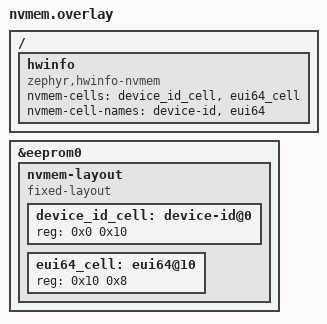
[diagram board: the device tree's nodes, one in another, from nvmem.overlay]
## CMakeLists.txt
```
# SPDX-License-Identifier: Apache-2.0

cmake_minimum_required(VERSION 3.28.0)
find_package(Zephyr REQUIRED HINTS $ENV{ZEPHYR_BASE})
project(integration)

target_sources(app PRIVATE src/main.c)
target_sources_ifdef(CONFIG_HWINFO_NVMEM app PRIVATE src/nvmem.c)
```

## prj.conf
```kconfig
CONFIG_HWINFO=y
CONFIG_ZTEST=y
```

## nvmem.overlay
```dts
/*
 * SPDX-FileCopyrightText: Copyright (c) 2026 Basalte bv
 * SPDX-License-Identifier: Apache-2.0
 */

/ {
	hwinfo {
		compatible = "zephyr,hwinfo-nvmem";
		nvmem-cells = <&device_id_cell>, <&eui64_cell>;
		nvmem-cell-names = "device-id", "eui64";
	};
};

&eeprom0 {
	nvmem-layout {
		compatible = "fixed-layout";
		#address-cells = <1>;
		#size-cells = <1>;

		device_id_cell: device-id@0 {
			reg = <0x0 0x10>;
			#nvmem-cell-cells = <0>;
		};

		eui64_cell: eui64@10 {
			reg = <0x10 0x8>;
			#nvmem-cell-cells = <0>;
		};
	};
};
```

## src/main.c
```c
/*
 * Copyright (c) 2019 Alexander Wachter
 *
 * SPDX-License-Identifier: Apache-2.0
 */
#include <zephyr/drivers/hwinfo.h>
#include <zephyr/ztest.h>
#include <strings.h>
#include <errno.h>

/*
 * @addtogroup t_hwinfo_get_device_id_api
 * @{
 * @defgroup t_hwinfo_get_device_id test_hwinfo_get_device_id
 * @brief TestPurpose: verify device id get works
 * @details
 * - Test Steps
 *   -# Read the ID
 *   -# Check if to many bytes are written to the buffer
 *   -# Check if UID is plausible
 * - Expected Results
 *   -# Device uid with correct length should be written to the buffer.
 * @}
 */

#define BUFFER_LENGTH 17
#define BUFFER_CANARY 0xFF

ZTEST(hwinfo_device_id_api, test_device_id_get)
{
	uint8_t buffer_1[BUFFER_LENGTH];
	uint8_t buffer_2[BUFFER_LENGTH];
	ssize_t length_read_1, length_read_2;
	int i;

	length_read_1 = hwinfo_get_device_id(buffer_1, 1);
	if (length_read_1 == -ENOSYS) {
		ztest_test_skip();
		return;
	}

	zassert_false((length_read_1 < 0),
		      "Unexpected negative return value: %zd", length_read_1);
	zassert_not_equal(length_read_1, 0, "Zero bytes read");
	zassert_equal(length_read_1, 1, "Length not adhered");

	memset(buffer_1, BUFFER_CANARY, sizeof(buffer_1));

	length_read_1 = hwinfo_get_device_id(buffer_1, BUFFER_LENGTH - 1);
	zassert_equal(buffer_1[length_read_1], BUFFER_CANARY,
		      "Too many bytes are written");

	memcpy(buffer_2, buffer_1, length_read_1);

	for (i = 0; i < BUFFER_LENGTH; i++) {
		buffer_1[i] ^= 0xA5;
	}

	length_read_2 = hwinfo_get_device_id(buffer_1, BUFFER_LENGTH - 1);
	zassert_equal(length_read_1, length_read_2, "Length varied");

	zassert_equal(buffer_1[length_read_1], (BUFFER_CANARY ^ 0xA5),
		      "Too many bytes are written");

	for (i = 0; i < length_read_1; i++) {
		zassert_equal(buffer_1[i], buffer_2[i],
			      "Two consecutively readings don't match");
	}
}

/*
 * @addtogroup t_hwinfo_get_reset_cause_api
 * @{
 * @defgroup t_hwinfo_get_reset_cause test_hwinfo_get_reset_cause
 * @brief TestPurpose: verify get reset cause works.
 * @details
 * - Test Steps
 *   -# Set target buffer to a known value
 *   -# Read the reset cause
 *   -# Check if target buffer has been altered
 * - Expected Results
 *   -# Target buffer contents should be changed after the call.
 * @}
 */

ZTEST(hwinfo_device_id_api, test_get_reset_cause)
{
	uint32_t cause;
	ssize_t ret;

	/* Set `cause` to a known value prior to call. */
	cause = 0xDEADBEEF;

	ret = hwinfo_get_reset_cause(&cause);
	if (ret == -ENOSYS) {
		ztest_test_skip();
		return;
	}

	zassert_false((ret < 0),
		      "Unexpected negative return value: %zd", ret);

	/* Verify that `cause` has been changed. */
	zassert_not_equal(cause, 0xDEADBEEF, "Reset cause not written.");
}

/*
 * @addtogroup t_hwinfo_clear_reset_cause_api
 * @{
 * @defgroup t_hwinfo_clear_reset_cause test_hwinfo_clear_reset_cause
 * @brief TestPurpose: verify clear reset cause works. This may
 *        not work on some platforms, depending on how reset cause register
 *        works on that SoC.
 * @details
 * - Test Steps
 *   -# Read the reset cause and store the result
 *   -# Call clear reset cause
 *   -# Read the reset cause again
 *   -# Check if the two readings match
 * - Expected Results
 *   -# Reset cause value should change after calling clear reset cause.
 * @}
 */
ZTEST(hwinfo_device_id_api, test_clear_reset_cause)
{
	uint32_t cause_1, cause_2;
	ssize_t ret;

	ret = hwinfo_get_reset_cause(&cause_1);
	if (ret == -ENOSYS) {
		ztest_test_skip();
		return;
	}

	zassert_false((ret < 0),
		      "Unexpected negative return value: %zd", ret);

	ret = hwinfo_clear_reset_cause();
	if (ret == -ENOSYS) {
		ztest_test_skip();
		return;
	}

	zassert_false((ret < 0),
		      "Unexpected negative return value: %zd", ret);

	ret = hwinfo_get_reset_cause(&cause_2);
	if (ret == -ENOSYS) {
		ztest_test_skip();
		return;
	}

	zassert_false((ret < 0),
		      "Unexpected negative return value: %zd", ret);

	/* Verify that `cause` has been changed. */
	zassert_not_equal(cause_1, cause_2,
		"Reset cause did not change after clearing");
}

/*
 * @addtogroup t_hwinfo_get_reset_cause_api
 * @{
 * @defgroup t_hwinfo_get_supported_reset_cause test_hwinfo_get_supported_reset_cause
 * @brief TestPurpose: verify get supported reset cause works.
 * @details
 * - Test Steps
 *   -# Set target buffer to a known value
 *   -# Read the reset cause
 *   -# Check if target buffer has been altered
 * - Expected Results
 *   -# Target buffer contents should be changed after the call.
 * @}
 */
ZTEST(hwinfo_device_id_api, test_get_supported_reset_cause)
{
	uint32_t supported;
	ssize_t ret;

	/* Set `supported` to a known value prior to call. */
	supported = 0xDEADBEEF;

	ret = hwinfo_get_supported_reset_cause(&supported);
	if (ret == -ENOSYS) {
		ztest_test_skip();
		return;
	}

	zassert_false((ret < 0),
		      "Unexpected negative return value: %zd", ret);

	/* Verify that `supported` has been changed. */
	zassert_not_equal(supported, 0xDEADBEEF,
					"Supported reset cause not written.");
}


ZTEST_SUITE(hwinfo_device_id_api, NULL, NULL, NULL, NULL, NULL);
```

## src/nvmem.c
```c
/*
 * SPDX-FileCopyrightText: Copyright (c) 2026 Basalte bv
 * SPDX-License-Identifier: Apache-2.0
 */

#include <string.h>

#include <zephyr/drivers/hwinfo.h>
#include <zephyr/nvmem.h>
#include <zephyr/ztest.h>

#define HWINFO_NODE DT_COMPAT_GET_ANY_STATUS_OKAY(zephyr_hwinfo_nvmem)

#define BUFFER_CANARY 0x5AU

#define DEVICE_ID_SIZE DT_REG_SIZE(DT_NVMEM_CELL_BY_NAME(HWINFO_NODE, device_id))
#define EUI64_SIZE     DT_REG_SIZE(DT_NVMEM_CELL_BY_NAME(HWINFO_NODE, eui64))

static const struct nvmem_cell device_id_cell = NVMEM_CELL_GET_BY_NAME(HWINFO_NODE, device_id);
static const struct nvmem_cell eui64_cell = NVMEM_CELL_GET_BY_NAME(HWINFO_NODE, eui64);

static uint8_t device_id[DEVICE_ID_SIZE];
static uint8_t eui64[EUI64_SIZE];
static int seed_ret;

static void *hwinfo_nvmem_setup(void)
{
	for (size_t i = 0; i < sizeof(device_id); i++) {
		device_id[i] = (uint8_t)(0xA0U + i);
	}

	for (size_t i = 0; i < sizeof(eui64); i++) {
		eui64[i] = (uint8_t)(0x11U * i);
	}

	seed_ret = nvmem_cell_write(&device_id_cell, device_id, 0, sizeof(device_id));
	if (seed_ret == 0) {
		seed_ret = nvmem_cell_write(&eui64_cell, eui64, 0, sizeof(eui64));
	}

	return NULL;
}

ZTEST(hwinfo_nvmem, test_device_id_content)
{
	uint8_t buffer[DEVICE_ID_SIZE * 2];
	ssize_t length;

	zassert_equal(seed_ret, 0, "Failed to seed the nvmem cells: %d", seed_ret);

	memset(buffer, BUFFER_CANARY, sizeof(buffer));
	length = hwinfo_get_device_id(buffer, sizeof(buffer));
	zexpect_equal(length, (ssize_t)DEVICE_ID_SIZE, "Length not clamped to the cell size: %zd",
		      length);
	zexpect_mem_equal(buffer, device_id, DEVICE_ID_SIZE,
			  "Device ID does not match the cell content");
	zexpect_equal(buffer[DEVICE_ID_SIZE], BUFFER_CANARY,
		      "Bytes beyond the device ID were written");

	memset(buffer, BUFFER_CANARY, sizeof(buffer));
	length = hwinfo_get_device_id(buffer, 4);
	zexpect_equal(length, 4, "Length not clamped to the request: %zd", length);
	zexpect_mem_equal(buffer, device_id, 4, "Device ID does not match the cell content");
	zexpect_equal(buffer[4], BUFFER_CANARY, "Bytes beyond the requested length were written");
}

ZTEST(hwinfo_nvmem, test_eui64_content)
{
	uint8_t buffer[EUI64_SIZE];
	int ret;

	zassert_equal(seed_ret, 0, "Failed to seed the nvmem cells: %d", seed_ret);

	ret = hwinfo_get_device_eui64(buffer);
	zexpect_equal(ret, 0, "Failed to get the EUI64: %d", ret);
	zexpect_mem_equal(buffer, eui64, sizeof(eui64), "EUI64 does not match the cell content");
}

ZTEST_SUITE(hwinfo_nvmem, NULL, hwinfo_nvmem_setup, NULL, NULL, NULL);
```
